# ADuCM302x register map
Vendor: Analog Devices; Series: ADuCM302x; File version: 1p0
CPU: CM3 r0p1, little endian, no MPU, no FPU, 3 interrupt priority bits
Registers are 32-bit, read-write, reset 0x0 unless marked. A register's access mark holds for its fields unless they carry their own. Offsets are from the block's base; [hi:lo] are bit positions; {n}, {i} and the like mark numbered series.

## ADC0
Base 0x40007000
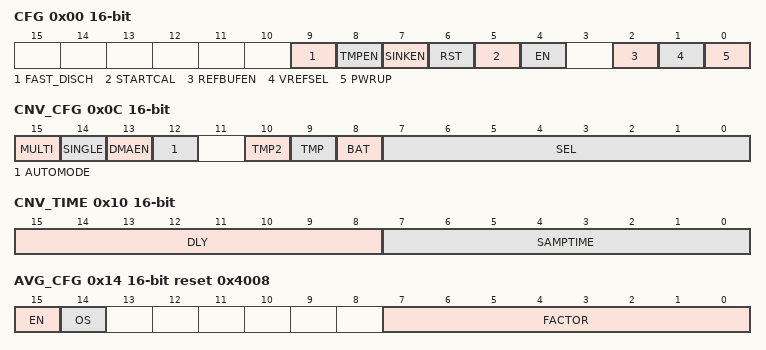
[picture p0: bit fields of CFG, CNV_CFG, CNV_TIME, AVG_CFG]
0x00 CFG 16-bit — ADC Configuration
  [9] FAST_DISCH range 0x00000000..0x00000001 — For fast switchover of Vref from higher to lower reference voltage
  [8] TMPEN range 0x00000000..0x00000001 — To power up temperature sensor
  [7] SINKEN range 0x00000000..0x00000001 — To enable additional 50 uA sink current capability @1.25 V, 100 uA current capability @2.5 V
  [6] RST range 0x00000000..0x00000001 — Resets internal buffers and registers when high
  [5] STARTCAL range 0x00000000..0x00000001 — To start a new offset calibration cycle
  [4] EN range 0x00000000..0x00000001 — To enable ADC subsystem
  [2] REFBUFEN — To enable internal reference buffer
    0=EN000 (External reference is used); 1=EN001 (Reference buffer is enabled)
  [1] VREFSEL — To select Vref as 1.25 V or 2.5 V
    0=V_2p5 (Vref = 2.5V); 1=V_1p25 (Vref = 1.25V)
  [0] PWRUP range 0x00000000..0x00000001 — Powering up the ADC
0x04 PWRUP 16-bit reset 0x20E — ADC Power-up Time
  [9:0] WAIT range 0x00000000..0x000003FF — Program this with 526/PCLKDIVCNT
0x08 CAL_WORD 16-bit reset 0x40 — Calibration Word
  [6:0] VALUE range 0x00000000..0x0000007F — Offset calibration word
0x0C CNV_CFG 16-bit — ADC Conversion Configuration
  [15] MULTI range 0x00000000..0x00000001 — Set to start multiple conversions
  [14] SINGLE range 0x00000000..0x00000001 — Set to start single conversion
  [13] DMAEN range 0x00000000..0x00000001 — To enable DMA channel
  [12] AUTOMODE range 0x00000000..0x00000001 — To enable auto mode
  [10] TMP2 range 0x00000000..0x00000001 — To select temperature measurement 2
  [9] TMP range 0x00000000..0x00000001 — To select temperature measurement 1
  [8] BAT range 0x00000000..0x00000001 — To enable battery monitoring
  [7:0] SEL range 0x00000000..0x000000FF — To select channel(s) to convert
0x10 CNV_TIME 16-bit — ADC Conversion Time
  [15:8] DLY range 0x00000000..0x000000FF — Delay between two consecutive conversions in terms of number of ACLK cycles
  [7:0] SAMPTIME range 0x00000000..0x000000FF — Number of clock cycles (ACLK) required for sampling
0x14 AVG_CFG 16-bit reset 0x4008 — Averaging Configuration
  [15] EN range 0x00000000..0x00000001 — To enable averaging on Channels enabled in enable register
  [14] OS range 0x00000000..0x00000001 — Enable oversampling
  [7:0] FACTOR range 0x00000000..0x000000FF — Program averaging factor for averaging enabled channels (1-256)
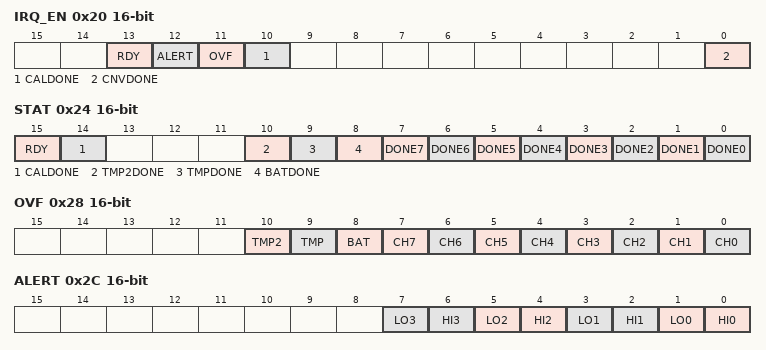
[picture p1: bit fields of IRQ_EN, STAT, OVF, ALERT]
0x20 IRQ_EN 16-bit — Interrupt Enable
  [13] RDY range 0x00000000..0x00000001 — Set to enable interrupt when ADC is ready to convert
  [12] ALERT range 0x00000000..0x00000001 — Set to enable interrupt on crossing lower or higher limit
  [11] OVF range 0x00000000..0x00000001 — Set to enable interrupt in case of overflow
  [10] CALDONE range 0x00000000..0x00000001 — Set it to enable interrupt for calibration done
  [0] CNVDONE range 0x00000000..0x00000001 — Set it to enable interrupt after conversion is done
0x24 STAT 16-bit — ADC Status
  [15] RDY range 0x00000000..0x00000001 — Indicates ADC is ready to start converting, when using external reference buffer
  [14] CALDONE range 0x00000000..0x00000001 — Indicates calibration is done
  [10] TMP2DONE range 0x00000000..0x00000001 — Indicates conversion is done for temperature sensing 2
  [9] TMPDONE range 0x00000000..0x00000001 — Indicates conversion is done for temperature sensing
  [8] BATDONE range 0x00000000..0x00000001 — Indicates conversion done for battery monitoring
  [n] DONE{n} range 0x00000000..0x00000001 (n=0..7) — Indicates conversion done on Channel {n}
0x28 OVF 16-bit — Overflow of Output Registers
  [10] TMP2 range 0x00000000..0x00000001 — Indicates overflow in Temperature 2 output register
  [9] TMP range 0x00000000..0x00000001 — Indicates overflow in Temperature output register
  [8] BAT range 0x00000000..0x00000001 — Indicates overflow in Battery monitoring output register
  [n] CH{n} range 0x00000000..0x00000001 (n=0..7) — Indicates overflow in Channel {n} output register
0x2C ALERT 16-bit — Alert Indication
  [2n+1] LO{n} range 0x00000000..0x00000001 (n=0..3) — Channel {n} Low alert status
  [2n] HI{n} range 0x00000000..0x00000001 (n=0..3) — Channel {n} High alert status
{0x30+4i} CH{i}_OUT 16-bit (i=0..7) — Conversion Result Channel {i}
  [15:0] RESULT ro — Conversion result of Channel {i} is stored here
0x50 BAT_OUT 16-bit — Battery Monitoring Result
  [15:0] RESULT ro — Conversion result of battery monitoring is stored here
0x54 TMP_OUT 16-bit — Temperature Result
  [15:0] RESULT ro — Conversion result of Temperature measurement 1 is stored here
0x58 TMP2_OUT 16-bit — Temperature Result 2
  [15:0] RESULT ro — Conversion result of Temperature measurement 2 is stored here
0x5C DMA_OUT 16-bit — DMA Output Register
  [15:0] RESULT ro — Register to store conversion result for DMA
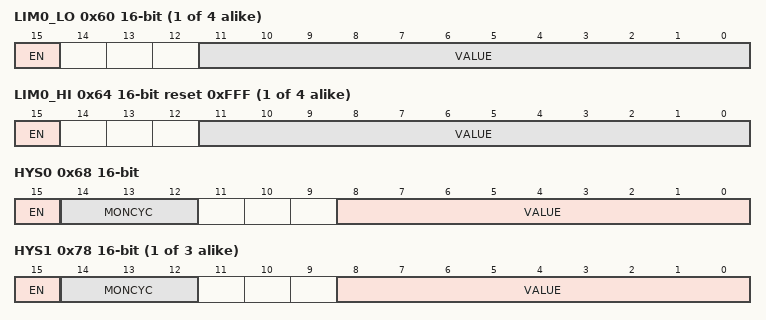
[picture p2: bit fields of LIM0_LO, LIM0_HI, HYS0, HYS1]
{0x60+0x10*i} LIM{i}_LO 16-bit (i=0..3) — Channel {i} Low Limit
  [15] EN range 0x00000000..0x00000001 — To enable low limit comparison on Channel {i}
  [11:0] VALUE range 0x00000000..0x00000FFF — Low limit value for Channel {i}
{0x64+0x10*i} LIM{i}_HI 16-bit reset 0xFFF (i=0..3) — Channel {i} High Limit
  [15] EN range 0x00000000..0x00000001 — To enable high limit comparison on Channel {i}
  [11:0] VALUE range 0x00000000..0x00000FFF — High limit value for Channel {i}
0x68 HYS0 16-bit — Channel 0 Hysteresis
  [15] EN range 0x00000000..0x00000001 — To enable hysteresis for comparison on Channel 0
  [14:12] MONCYC range 0x00000000..0x00000007 — Program number of conversion cycles to monitor channel 0 before raising alert
  [8:0] VALUE range 0x00000000..0x000001FF — Hysteresis value for Channel 0
{0x68+0x10*i} HYS{i} 16-bit (i=1..3) — Channel {i} Hysteresis
  [15] EN range 0x00000000..0x00000001 — To enable hysteresis for comparison on Channel {i}
  [14:12] MONCYC range 0x00000000..0x00000007 — Program number of conversion cycles to monitor Channel {i} before raising alert
  [8:0] VALUE range 0x00000000..0x000001FF — Hysteresis value for Channel {i}
0xC0 CFG1 16-bit reset 0x400 — Reference Buffer Low Power Mode
  [0] RBUFLP range 0x00000000..0x00000001 — Enable low-power mode for reference buffer
